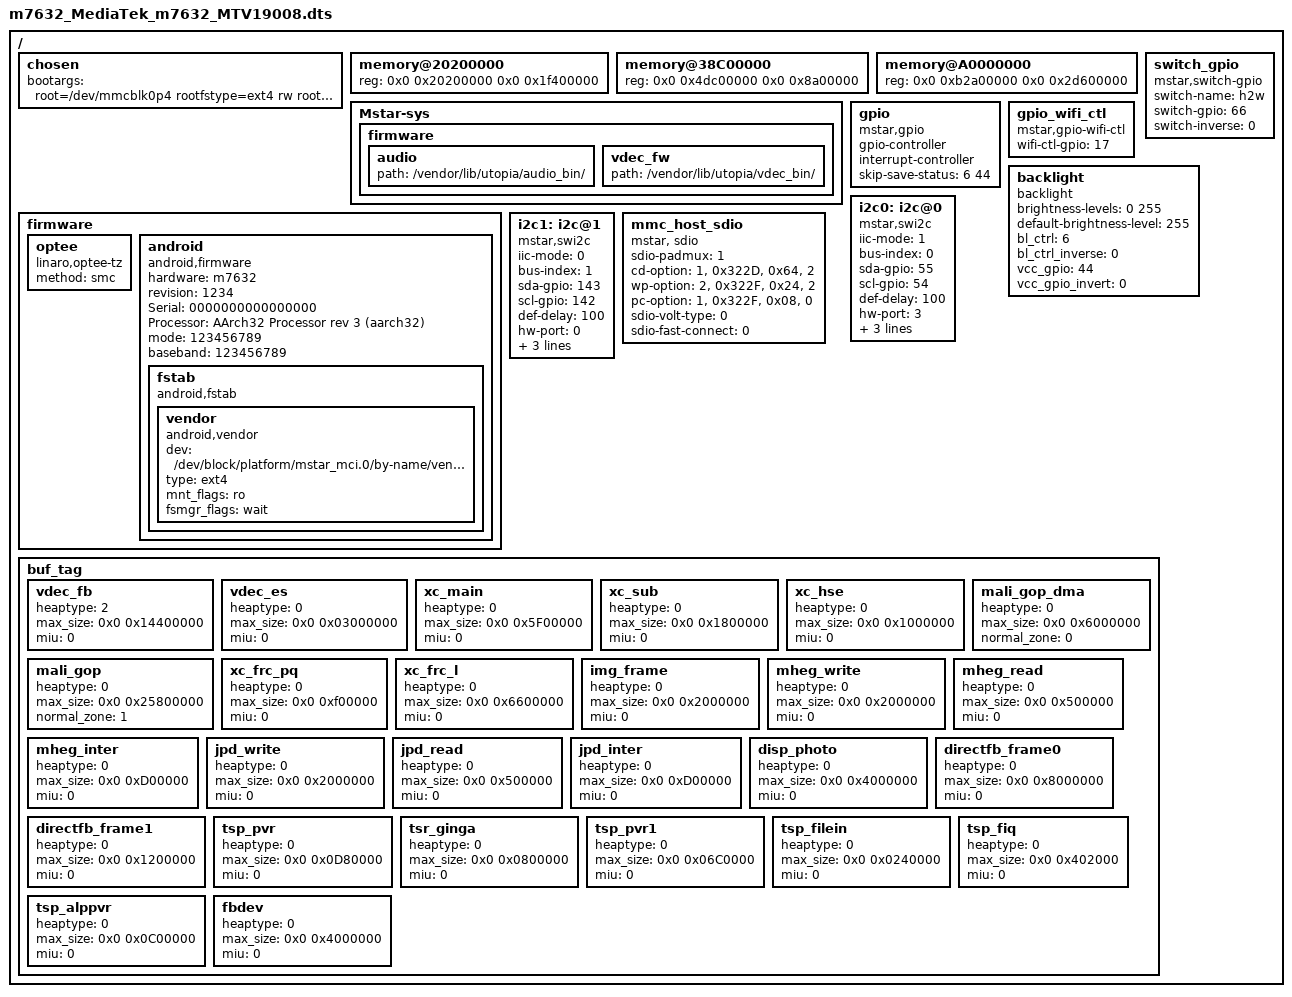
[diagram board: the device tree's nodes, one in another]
/dts-v1/;
#include "../../../../drivers/mstar2/hal/m7632/gpio/mhal_gpio_reg.h"
#include "m7632.dtsi"

/ {
	chosen {
		bootargs = "root=/dev/mmcblk0p4 rootfstype=ext4 rw rootwait init=/sbin/init ip=dhcp console=ttyS0,115200,LX_MEM=0x02000000";
	};

	memory@20200000 {
		device_type = "memory";
		reg = <0x0 0x20200000 0x0 0x1f400000>;
	};

	memory@38C00000 {
		device_type = "memory";
		reg = <0x0 0x4dc00000 0x0 0x8a00000>;
	};

	memory@A0000000 {
		device_type = "memory";
		reg = <0x0 0xb2a00000 0x0 0x2d600000>;
	};

	Mstar-sys {
		firmware {
			audio {
				path = "/vendor/lib/utopia/audio_bin/";
			};
			vdec_fw {
				path = "/vendor/lib/utopia/vdec_bin/";
			};
		};
	};

	firmware {
		optee {
			compatible = "linaro,optee-tz";
			method = "smc";
		};

		android {
			compatible = "android,firmware";
			hardware ="m7632";
			revision ="1234";
			Serial   ="0000000000000000";
			Processor ="AArch32 Processor rev 3 (aarch32)";
			mode ="123456789";
			baseband ="123456789";

			fstab {
				compatible = "android,fstab";

				vendor {
					compatible = "android,vendor";
					dev = "/dev/block/platform/mstar_mci.0/by-name/vendor";
					type = "ext4";
					mnt_flags = "ro";
					fsmgr_flags = "wait";
				};
			};
		};
	};

	/* example of consume a gpio pin with mapped irq
	foo{
		interrupt-parent = <&gpio>;
		interrupts = <0 LEVEL_HIGH>;
	}
	*/

	gpio: gpio {
		compatible = "mstar,gpio";
		gpio-controller;
		#gpio-cells = <1>;
		interrupt-controller;
		skip-save-status = <6 44>;
		#interrupt-cells = <2>; /* cell name GPIO_PAD, trigger-type*/
	};

	switch_gpio {
		compatible = "mstar,switch-gpio";
		switch-name = "h2w";
		switch-gpio = <66>;
		switch-inverse = <0>;
	};

	gpio_wifi_ctl {
		compatible = "mstar,gpio-wifi-ctl";
		wifi-ctl-gpio = <17>;
	};

	backlight {
		compatible = "backlight";
		brightness-levels = <0 255>;
		default-brightness-level = <255>;
		bl_ctrl = <6>;
		bl_ctrl_inverse = <0>;
		vcc_gpio = <44>;
		vcc_gpio_invert = <0>;
		/* led-pwm-control-support; */
		/* led-pwm-control-channel = <0>; */
		/* led-pwm-control-resume-period = <0xb71a>; */
		/* led-pwm-control-resume-duty = <0xb71a>; */
		/* led-pwm-control-resume-div = <0xff>; */
		/* led-pwm-control-resume-polarity = <0>; */
		/* led-pwm-control-suspend-period = <0xb71a>; */
		/* led-pwm-control-suspend-duty = <0xb71a>; */
		/* led-pwm-control-suspend-div = <0xff>; */
		/* led-pwm-control-suspend-polarity = <0>; */
	};

	i2c0: i2c@0 {
		compatible = "mstar,swi2c";
		iic-mode = <1>;     /* i2c-mode: 0:swi2c; 1:hwi2c */
		bus-index = <0>;    /* swi2c setting: bus index */
		sda-gpio = <55>;    /* swi2c setting: sda pad */
		scl-gpio = <54>;    /* swi2c setting: scl pad */
		def-delay = <100>;  /* swi2c setting: clk */
		hw-port = <3>;      /* hwi2c setting: port */
		pad-mux = <25>;     /* hwi2c setting: pad mux */
		speed-khz = <100>;  /* hwi2c setting: clk */
		retries = <5>;      /* Unused */
		status = "okay";    /* Unused */
	};

	i2c1: i2c@1 {
		compatible = "mstar,swi2c";
		iic-mode = <0>;     /* i2c-mode: 0:swi2c; 1:hwi2c */
		bus-index = <1>;    /* swi2c setting: bus index */
		sda-gpio = <143>;   /* swi2c setting: sda pad */
		scl-gpio = <142>;   /* swi2c setting: scl pad */
		def-delay = <100>;  /* swi2c setting: clk */
		hw-port = <0>;      /* hwi2c setting: port */
		pad-mux = <0>;      /* hwi2c setting: pad mux */
		speed-khz = <100>;  /* hwi2c setting: clk */
		retries = <5>;      /* Unused */
		status = "okay";    /* Unused */
	};

	mmc_host_sdio {
		compatible = "mstar, sdio";
		sdio-padmux = <1>;
		cd-option = <1>,<0x322D>,<0x64>,<2>;
		wp-option = <2>,<0x322F>,<0x24>,<2>;
		pc-option = <1>,<0x322F>,<0x08>,<0>;
		sdio-volt-type = <0>;
		sdio-fast-connect = <0>;
	};

	buf_tag {
	/* heaptype: HEAP_TYPE_IOMMU = 0, HEAP_TYPE_CMA= 1,  HEAP_TYPE_NON_MMA = 2*/
	/* miutype:  UMA_OR_MIU0 = 0, MIU_1 = 1 */
		vdec_fb {
			heaptype = <2>;
			max_size = <0x0 0x14400000>;
			miu = <0>;
		};
		vdec_es {
			heaptype = <0>;
			max_size = <0x0 0x03000000>;
			miu = <0>;
		};
		xc_main {
			heaptype = <0>;
			max_size = <0x0 0x5F00000>;
			miu = <0>;
		};
		xc_sub {
			heaptype = <0>;
			max_size = <0x0 0x1800000>;
			miu = <0>;
		};
		xc_hse {
			heaptype = <0>;
			max_size = <0x0 0x1000000>;
			miu = <0>;
		};
		mali_gop_dma {
			heaptype = <0>;
			max_size = <0x0 0x6000000>;
			normal_zone = <0>;
		};
		mali_gop {
			heaptype = <0>;
			max_size = <0x0 0x25800000>;
			normal_zone = <1>;
		};
		xc_frc_pq {
			heaptype = <0>;
			max_size = <0x0 0xf00000>;
			miu = <0>;
		};
		xc_frc_l {
			heaptype = <0>;
			max_size = <0x0 0x6600000>;
			miu = <0>;
		};
		img_frame {
			heaptype = <0>;
			max_size = <0x0 0x2000000>;
			miu = <0>;
		};
		mheg_write {
			heaptype = <0>;
			max_size = <0x0 0x2000000>;
			miu = <0>;
		};
		mheg_read {
			heaptype = <0>;
			max_size = <0x0 0x500000>;
			miu = <0>;
		};
		mheg_inter {
			heaptype = <0>;
			max_size = <0x0 0xD00000>;
			miu = <0>;
		};
		jpd_write {
			heaptype = <0>;
			max_size = <0x0 0x2000000>;
			miu = <0>;
		};
		jpd_read {
			heaptype = <0>;
			max_size = <0x0 0x500000>;
			miu = <0>;
		};
		jpd_inter {
			heaptype = <0>;
			max_size = <0x0 0xD00000>;
			miu = <0>;
		};
		disp_photo {
			heaptype = <0>;
			max_size = <0x0 0x4000000>;
			miu = <0>;
		};
		directfb_frame0 {
			heaptype = <0>;
			max_size = <0x0 0x8000000>;
			miu = <0>;
		};
		directfb_frame1 {
			heaptype = <0>;
			max_size = <0x0 0x1200000>;
			miu = <0>;
		};
		tsp_pvr {
			heaptype = <0>;
			max_size = <0x0 0x0D80000>;
			miu = <0>;
		};
        tsr_ginga {
             heaptype = <0>;
             max_size = <0x0 0x0800000>;
             miu = <0>;
         };
		tsp_pvr1 {
			heaptype = <0>;
			max_size = <0x0 0x06C0000>;
			miu = <0>;
		};
		tsp_filein {
			heaptype = <0>;
			max_size = <0x0 0x0240000>;
			miu = <0>;
		};
		tsp_fiq {
			heaptype = <0>;
			max_size = <0x0 0x402000>;
			miu = <0>;
		};
		tsp_alppvr {
			heaptype = <0>;
			max_size = <0x0 0x0C00000>;
			miu = <0>;
		};
		fbdev {
			heaptype = <0>;
			max_size = <0x0 0x4000000>;
			miu = <0>;
		};
	};
};
